AUTOSAR XML (schema 4-2-2)
package /ComponentTypes
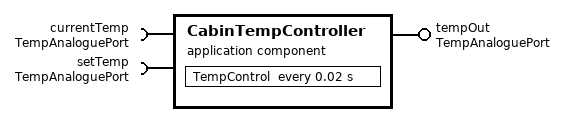
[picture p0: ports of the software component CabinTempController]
  application sw component type CabinTempController
    require port currentTemp: required-com-specs=[{data-element=tempIn, init-value=0}, {data-element=tempOut, init-value=0}], required-interface=TempAnaloguePort
    require port setTemp: required-com-specs=[{data-element=tempIn, init-value=0}, {data-element=tempOut, init-value=0}], required-interface=TempAnaloguePort
    provide port tempOut: provided-com-specs=[{data-element=tempIn, init-value=0}, {data-element=tempOut, init-value=0}], provided-interface=TempAnaloguePort
    behavior CabinTempController_InternalBehavior: data-type-mapping=tempMapSet
      timing event TMT_TempControl: start-on-event=TempControl, period=0.02
      data received event DRT_TempControl_setTemp_tempIn: start-on-event=TempControl, data=setTemp.tempIn
      runnable TempControl
        data-receive-point-by-arguments:
          4 x access:
            REC_currentTemp_tempIn: accessed-variable=currentTemp.tempIn
            REC_currentTemp_tempOut: accessed-variable=currentTemp.tempOut
            REC_setTemp_tempIn: accessed-variable=setTemp.tempIn
            REC_setTemp_tempOut: accessed-variable=setTemp.tempOut
        data-send-points:
          access SEND_tempOut_tempOut: accessed-variable=tempOut.tempOut
          access SEND_tempOut_tempIn: accessed-variable=tempOut.tempIn
  swc implementation CabinTempController_Implementation: behavior=CabinTempController_InternalBehavior
